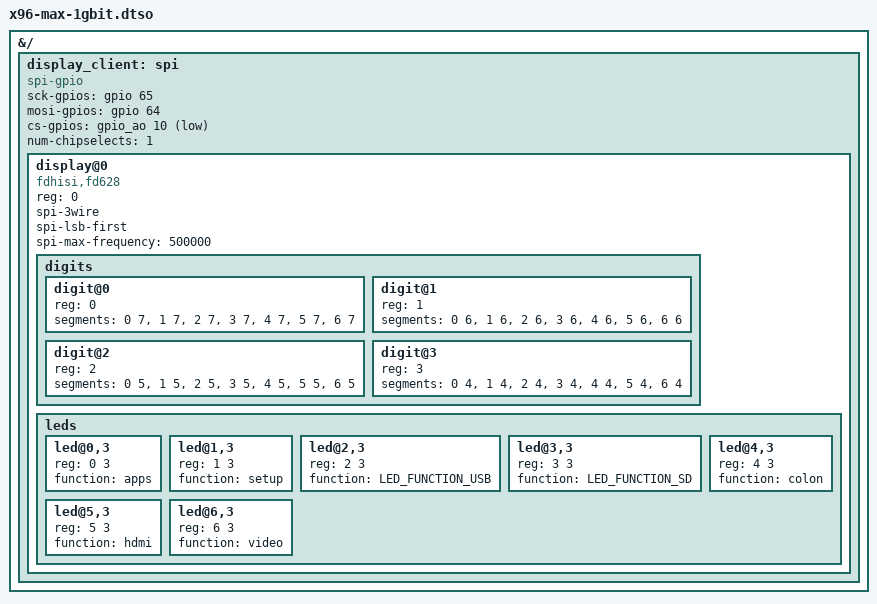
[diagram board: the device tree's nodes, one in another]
/dts-v1/;
/plugin/;

#include <dt-bindings/gpio/gpio.h>
#include <dt-bindings/leds/common.h>

&{/} {

	display_client: spi {
		#address-cells = <1>;
		#size-cells = <0>;
		compatible = "spi-gpio";
		sck-gpios = <&gpio 65 GPIO_ACTIVE_HIGH>;
		mosi-gpios = <&gpio 64 GPIO_ACTIVE_HIGH>;
		cs-gpios = <&gpio_ao 10 GPIO_ACTIVE_LOW>;
		num-chipselects = <1>;

		display@0 {
			compatible = "fdhisi,fd628", "titanmec,tm1628";
			reg = <0>;
			spi-3wire;
			spi-lsb-first;
			spi-max-frequency = <500000>;

			digits {
				#address-cells = <1>;
				#size-cells = <0>;
				digit@0 {
					reg = <0>;
					segments = <0 7>,
						   <1 7>,
						   <2 7>,
						   <3 7>,
						   <4 7>,
						   <5 7>,
						   <6 7>;
				};
				digit@1 {
					reg = <1>;
					segments = <0 6>,
						   <1 6>,
						   <2 6>,
						   <3 6>,
						   <4 6>,
						   <5 6>,
						   <6 6>;
				};
				digit@2 {
					reg = <2>;
					segments = <0 5>,
						   <1 5>,
						   <2 5>,
						   <3 5>,
						   <4 5>,
						   <5 5>,
						   <6 5>;
				};
				digit@3 {
					reg = <3>;
					segments = <0 4>,
						   <1 4>,
						   <2 4>,
						   <3 4>,
						   <4 4>,
						   <5 4>,
						   <6 4>;
				};
			};

			leds {
				#address-cells = <2>;
				#size-cells = <0>;
				led@0,3 {
					reg = <0 3>;
					function = "apps";
				};
				led@1,3 {
					reg = <1 3>;
					function = "setup";
				};
				led@2,3 {
					reg = <2 3>;
					function = LED_FUNCTION_USB;
				};
				led@3,3 {
					reg = <3 3>;
					function = LED_FUNCTION_SD;
				};
				led@4,3 {
					reg = <4 3>;
					function = "colon";
				};
				led@5,3 {
					reg = <5 3>;
					function = "hdmi";
				};
				led@6,3 {
					reg = <6 3>;
					function = "video";
				};
			};
		};
	};
};
